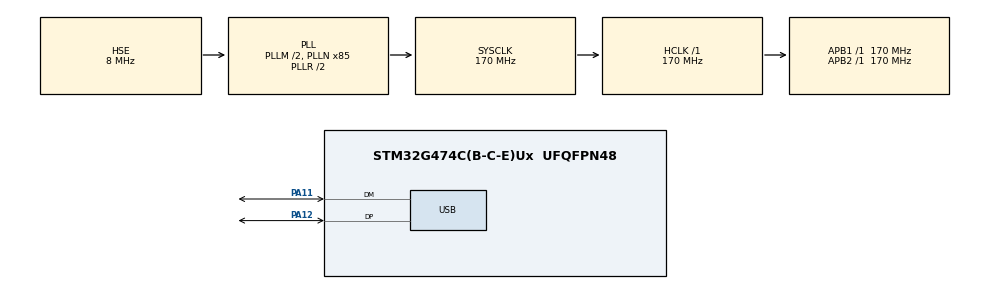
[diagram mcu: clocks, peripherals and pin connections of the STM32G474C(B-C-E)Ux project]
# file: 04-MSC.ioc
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Mcu.Family=STM32G4
Mcu.Name=STM32G474C(B-C-E)Ux
Mcu.Package=UFQFPN48
NVIC.PriorityGroup=NVIC_PRIORITYGROUP_4
NVIC.USB_LP_IRQn=true\:0\:0\:false\:false\:true\:false\:true\:true
PA11.Mode=Device
PA11.Signal=USB_DM
PA12.Mode=Device
PA12.Signal=USB_DP
PA13.Mode=Serial_Wire
PA13.Signal=SYS_JTMS-SWDIO
PA14.Mode=Serial_Wire
PA14.Signal=SYS_JTCK-SWCLK
PC14-OSC32_IN.Mode=LSE-External-Oscillator
PC14-OSC32_IN.Signal=RCC_OSC32_IN
PC15-OSC32_OUT.Mode=LSE-External-Oscillator
PC15-OSC32_OUT.Signal=RCC_OSC32_OUT
PF0-OSC_IN.Mode=HSE-External-Oscillator
PF0-OSC_IN.Signal=RCC_OSC_IN
PF1-OSC_OUT.Mode=HSE-External-Oscillator
PF1-OSC_OUT.Signal=RCC_OSC_OUT
ProjectManager.HeapSize=0x800
ProjectManager.StackSize=0x400
ProjectManager.TargetToolchain=MDK-ARM V5.32
RCC.ADC12Freq_Value=170000000
RCC.ADC345Freq_Value=170000000
RCC.AHBFreq_Value=170000000
RCC.APB1Freq_Value=170000000
RCC.APB1TimFreq_Value=170000000
RCC.APB2Freq_Value=170000000
RCC.APB2TimFreq_Value=170000000
RCC.CK48CLockSelection=RCC_USBCLKSOURCE_HSI48
RCC.CortexFreq_Value=170000000
RCC.EXTERNAL_CLOCK_VALUE=12288000
RCC.HCLKFreq_Value=170000000
RCC.HSE_VALUE=8000000
RCC.HSI48_VALUE=48000000
RCC.HSI_VALUE=16000000
RCC.PLLM=RCC_PLLM_DIV2
RCC.PLLN=85
RCC.PLLSourceVirtual=RCC_PLLSOURCE_HSE
RCC.RTCClockSelection=RCC_RTCCLKSOURCE_LSE
RCC.SYSCLKFreq_VALUE=170000000
RCC.SYSCLKSource=RCC_SYSCLKSOURCE_PLLCLK
RCC.USBFreq_Value=48000000
RCC.VCOOutputFreq_Value=340000000
USB_DEVICE.CLASS_NAME_FS=MSC
USB_DEVICE.MSC_MEDIA_PACKET=2048
USB_DEVICE.VirtualMode=Msc
USB_DEVICE.VirtualModeFS=Msc_FS
VP_RTC_VS_RTC_Activate.Mode=RTC_Enabled
VP_RTC_VS_RTC_Calendar.Mode=RTC_Calendar
VP_SYS_VS_DBSignals.Mode=DisableDeadBatterySignals
VP_USB_DEVICE_VS_USB_DEVICE_MSC_FS.Mode=MSC_FS
board=custom

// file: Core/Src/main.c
/* USER CODE BEGIN Header */
/*---------------------------------------
- WeAct Studio Official Link
- taobao: weactstudio.taobao.com
- aliexpress: weactstudio.aliexpress.com
- github: github.com/WeActStudio
- gitee: gitee.com/WeActStudio
- blog: blog.weactstudio.com
---------------------------------------*/
/**
  ******************************************************************************
  * @file           : main.c
  * @brief          : Main program body
  ******************************************************************************
  * @attention
  *
  * Copyright (c) 2023 STMicroelectronics.
  * All rights reserved.
  *
  * This software is licensed under terms that can be found in the LICENSE file
  * in the root directory of this software component.
  * If no LICENSE file comes with this software, it is provided AS-IS.
  *
  ******************************************************************************
  */
/* USER CODE END Header */
#include "main.h"
#include "rtc.h"
#include "usb_device.h"
#include "gpio.h"

/* USER CODE BEGIN Includes */
#include "flash_access.h"
/* USER CODE END Includes */

void SystemClock_Config(void);

int main(void)
{

  /* MCU Configuration--------------------------------------------------------*/

  /* Reset of all peripherals, Initializes the Flash interface and the Systick. */
  HAL_Init();

  /* Configure the system clock */
  SystemClock_Config();

  /* Initialize all configured peripherals */
  MX_GPIO_Init();
  MX_USB_Device_Init();
  MX_RTC_Init();
  /* USER CODE BEGIN 2 */

  #include "board.h"
  board_button_init();
  board_led_init();

  uint32_t tick,tick_now;
  tick = HAL_GetTick();
  tick_now = HAL_GetTick();

  /* USER CODE END 2 */

  /* Infinite loop */
  while (1)
  {

    /* USER CODE BEGIN 3 */
    tick_now = HAL_GetTick();
    if(board_button_getstate())
    {
      if(tick_now >= tick)
      {
        tick = tick_now + 100;
        board_led_toggle();
      }
    }
    else
    {
      if(tick_now >= tick)
      {
        tick = tick_now + 10;

        RTC_DateTypeDef sdatestructureget;
        RTC_TimeTypeDef stimestructureget;
        static uint8_t Seconds_o;

        /* Get the RTC current Time */
        HAL_RTC_GetTime(&hrtc, &stimestructureget, RTC_FORMAT_BIN);
        /* Get the RTC current Date */
        HAL_RTC_GetDate(&hrtc, &sdatestructureget, RTC_FORMAT_BIN);

        if(Seconds_o != stimestructureget.Seconds)
        {
          Seconds_o = stimestructureget.Seconds;

          board_led_set(1);
        }
        else
        {
          board_led_set(0);
        }
      }
    }
  }
  /* USER CODE END 3 */
}

void SystemClock_Config(void)
{
  RCC_OscInitTypeDef RCC_OscInitStruct = {0};
  RCC_ClkInitTypeDef RCC_ClkInitStruct = {0};

  /** Configure the main internal regulator output voltage
  */
  HAL_PWREx_ControlVoltageScaling(PWR_REGULATOR_VOLTAGE_SCALE1_BOOST);

  /** Configure LSE Drive Capability
  */
  HAL_PWR_EnableBkUpAccess();
  __HAL_RCC_LSEDRIVE_CONFIG(RCC_LSEDRIVE_LOW);

  /** Initializes the RCC Oscillators according to the specified parameters
  * in the RCC_OscInitTypeDef structure.
  */
  RCC_OscInitStruct.OscillatorType = RCC_OSCILLATORTYPE_HSI48|RCC_OSCILLATORTYPE_HSE
                              |RCC_OSCILLATORTYPE_LSE;
  RCC_OscInitStruct.HSEState = RCC_HSE_ON;
  RCC_OscInitStruct.LSEState = RCC_LSE_ON;
  RCC_OscInitStruct.HSI48State = RCC_HSI48_ON;
  RCC_OscInitStruct.PLL.PLLState = RCC_PLL_ON;
  RCC_OscInitStruct.PLL.PLLSource = RCC_PLLSOURCE_HSE;
  RCC_OscInitStruct.PLL.PLLM = RCC_PLLM_DIV2;
  RCC_OscInitStruct.PLL.PLLN = 85;
  RCC_OscInitStruct.PLL.PLLP = RCC_PLLP_DIV2;
  RCC_OscInitStruct.PLL.PLLQ = RCC_PLLQ_DIV2;
  RCC_OscInitStruct.PLL.PLLR = RCC_PLLR_DIV2;
  if (HAL_RCC_OscConfig(&RCC_OscInitStruct) != HAL_OK)
  {
    Error_Handler();
  }

  /** Initializes the CPU, AHB and APB buses clocks
  */
  RCC_ClkInitStruct.ClockType = RCC_CLOCKTYPE_HCLK|RCC_CLOCKTYPE_SYSCLK
                              |RCC_CLOCKTYPE_PCLK1|RCC_CLOCKTYPE_PCLK2;
  RCC_ClkInitStruct.SYSCLKSource = RCC_SYSCLKSOURCE_PLLCLK;
  RCC_ClkInitStruct.AHBCLKDivider = RCC_SYSCLK_DIV1;
  RCC_ClkInitStruct.APB1CLKDivider = RCC_HCLK_DIV1;
  RCC_ClkInitStruct.APB2CLKDivider = RCC_HCLK_DIV1;

  if (HAL_RCC_ClockConfig(&RCC_ClkInitStruct, FLASH_LATENCY_4) != HAL_OK)
  {
    Error_Handler();
  }
}

void Error_Handler(void)
{
  __disable_irq();
  while (1)
  {
  }
}
